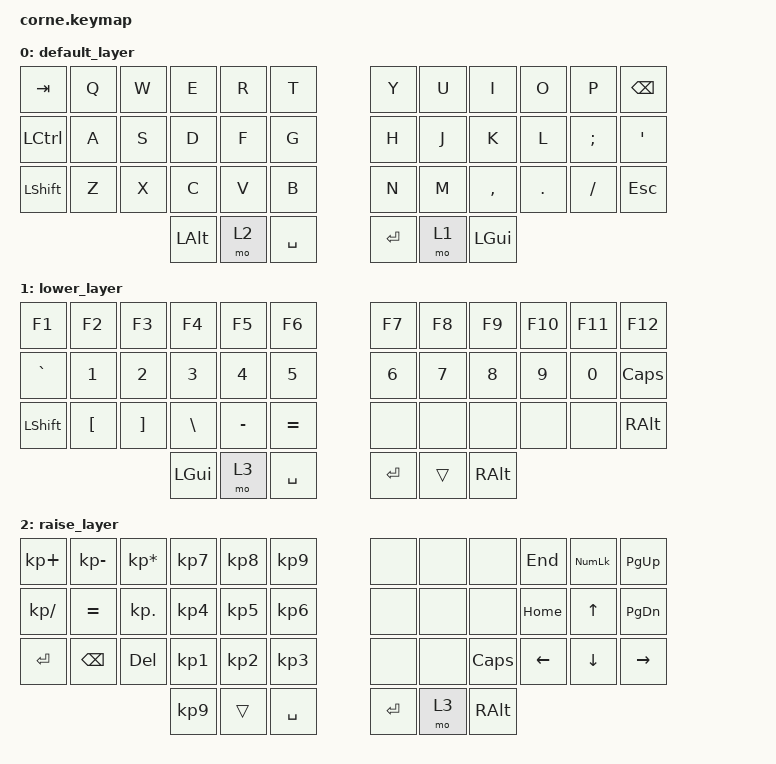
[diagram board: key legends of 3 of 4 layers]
/*
 * Copyright (c) 2020 The ZMK Contributors
 *
 * SPDX-License-Identifier: MIT
 */

#include <behaviors.dtsi>
#include <dt-bindings/zmk/bt.h>
#include <dt-bindings/zmk/keys.h>
#include <dt-bindings/zmk/rgb.h>

/ {
    behaviors {
        hm: homerow_mods {
            compatible = "zmk,behavior-hold-tap";
            label = "HOMEROW_MODS";
            #binding-cells = <2>;
            tapping-term-ms = <200>;
            quick_tap_ms = <0>;
            flavor = "tap-preferred";
            bindings = <&kp>, <&kp>;

            quick-tap-ms = <180>;
            global-quick-tap;
        };

        ltq: ltq {
            compatible = "zmk,behavior-hold-tap";
            label = "LTQ";
            bindings = <&mo>, <&kp>;

            #binding-cells = <2>;
            tapping-term-ms = <600>;
            global-quick-tap;
            quick-tap-ms = <400>;
        };
    };

    combos {
        compatible = "zmk,combos";

        left_bkt {
            bindings = <&kp LEFT_BRACKET>;
            key-positions = <4 3>;
            timeout-ms = <50>;
        };

        right_bkt {
            bindings = <&kp RBKT>;
            key-positions = <7 8>;
            timeout-ms = <50>;
        };

        left_par {
            bindings = <&kp LEFT_PARENTHESIS>;
            key-positions = <15 16>;
            timeout-ms = <50>;
        };

        right_par {
            bindings = <&kp RIGHT_PARENTHESIS>;
            key-positions = <19 20>;
            timeout-ms = <50>;
        };

        left_brace {
            bindings = <&kp LEFT_BRACE>;
            key-positions = <27 28>;
            timeout-ms = <50>;
        };

        right_brace {
            bindings = <&kp RIGHT_BRACE>;
            key-positions = <32 31>;
            timeout-ms = <50>;
        };

        bac {
            bindings = <&kp BACKSLASH>;
            key-positions = <5 6>;
        };

        pipe {
            bindings = <&kp PIPE>;
            key-positions = <17 18>;
        };
    };

    keymap {
        compatible = "zmk,keymap";

        default_layer {
            bindings = <
&kp TAB    &kp Q  &kp W  &kp E         &kp R  &kp T      &kp Y    &kp U  &kp I         &kp O    &kp P     &kp BSPC
&kp LCTRL  &kp A  &kp S  &kp D         &kp F  &kp G      &kp H    &kp J  &kp K         &kp L    &kp SEMI  &kp SQT
&kp LSHFT  &kp Z  &kp X  &kp C         &kp V  &kp B      &kp N    &kp M  &kp COMMA     &kp DOT  &kp FSLH  &kp ESC
                         &kp LEFT_ALT  &mo 2  &kp SPACE  &kp RET  &mo 1  &kp LEFT_GUI
            >;
        };

        lower_layer {
            bindings = <
&kp F1     &kp F2    &kp F3    &kp F4    &kp F5     &kp F6     &kp F7        &kp F8  &kp F9    &kp F10  &kp F11  &kp F12
&kp GRAVE  &kp N1    &kp N2    &kp N3    &kp N4     &kp N5     &kp NUMBER_6  &kp N7  &kp N8    &kp N9   &kp N0   &kp CLCK
&kp LSHFT  &kp LBKT  &kp RBKT  &kp BSLH  &kp MINUS  &kp EQUAL  &none         &none   &none     &none    &none    &kp RIGHT_ALT
                               &kp LGUI  &mo 3      &kp SPACE  &kp RET       &trans  &kp RALT
            >;
        };

        raise_layer {
            bindings = <
&kp KP_PLUS    &kp KP_MINUS   &kp KP_MULTIPLY  &kp KP_N7        &kp KP_N8  &kp KP_N9        &none    &none  &none     &kp END         &kp KP_NUM    &kp PAGE_UP
&kp KP_DIVIDE  &kp EQUAL      &kp KP_DOT       &kp KP_N4        &kp KP_N5  &kp KP_NUMBER_6  &none    &none  &none     &kp HOME        &kp UP_ARROW  &kp PAGE_DOWN
&kp ENTER      &kp BACKSPACE  &kp DEL          &kp KP_NUMBER_1  &kp KP_N2  &kp KP_N3        &none    &none  &kp CAPS  &kp LEFT_ARROW  &kp DOWN      &kp RIGHT
                                               &kp KP_NUMBER_9  &trans     &kp SPACE        &kp RET  &mo 3  &kp RALT
            >;
        };

        layer_3 {
            bindings = <
&trans  &none   &none       &none         &none         &none         &rgb_ug RGB_TOG                   &rgb_ug RGB_EFR                   &rgb_ug RGB_EFF  &trans  &trans  &trans
&trans  &none   &none       &bt BT_SEL 3  &bt BT_SEL 4  &none         &rgb_ug RGB_COLOR_HSB(177,16,44)  &rgb_ug RGB_COLOR_HSB(301,13,45)  &trans           &trans  &trans  &trans
&trans  &trans  &bt BT_CLR  &bt BT_SEL 0  &bt BT_SEL 1  &bt BT_SEL 2  &trans                            &trans                            &trans           &trans  &trans  &trans
                            &trans        &trans        &trans        &trans                            &trans
            >;
        };

        extra1 { status = "reserved"; };

        extra2 { status = "reserved"; };

        extra3 { status = "reserved"; };

        extra4 { status = "reserved"; };
    };
};
